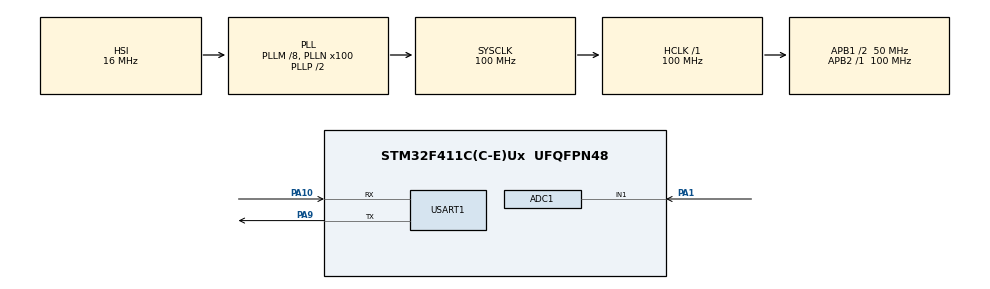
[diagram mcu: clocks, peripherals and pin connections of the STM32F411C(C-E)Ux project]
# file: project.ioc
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ADC1.Channel-0\#ChannelRegularConversion=ADC_CHANNEL_1
ADC1.ContinuousConvMode=ENABLE
ADC1.NbrOfConversionFlag=1
ADC1.Rank-0\#ChannelRegularConversion=1
ADC1.SamplingTime-0\#ChannelRegularConversion=ADC_SAMPLETIME_3CYCLES
ADC1.master=1
Dma.ADC1.0.Direction=DMA_PERIPH_TO_MEMORY
Dma.ADC1.0.FIFOMode=DMA_FIFOMODE_DISABLE
Dma.ADC1.0.Instance=DMA2_Stream0
Dma.ADC1.0.MemDataAlignment=DMA_MDATAALIGN_HALFWORD
Dma.ADC1.0.MemInc=DMA_MINC_ENABLE
Dma.ADC1.0.Mode=DMA_CIRCULAR
Dma.ADC1.0.PeriphDataAlignment=DMA_PDATAALIGN_HALFWORD
Dma.ADC1.0.PeriphInc=DMA_PINC_DISABLE
Dma.ADC1.0.Priority=DMA_PRIORITY_LOW
Dma.Request0=ADC1
FREERTOS.Tasks01=defaultTask,24,128,StartDefaultTask,Default,NULL,Dynamic,NULL,NULL
Mcu.Family=STM32F4
Mcu.Name=STM32F411C(C-E)Ux
Mcu.Package=UFQFPN48
NVIC.ADC_IRQn=true\:5\:0\:false\:false\:true\:true\:true\:true\:true
NVIC.DMA2_Stream0_IRQn=true\:5\:0\:false\:false\:true\:true\:false\:true\:true
NVIC.PriorityGroup=NVIC_PRIORITYGROUP_4
NVIC.TIM1_UP_TIM10_IRQn=true\:15\:0\:false\:false\:true\:false\:false\:true\:true
NVIC.TimeBase=TIM1_UP_TIM10_IRQn
NVIC.TimeBaseIP=TIM1
PA1.Signal=ADCx_IN1
PA10.Mode=Asynchronous
PA10.Signal=USART1_RX
PA13.Mode=Serial_Wire
PA13.Signal=SYS_JTMS-SWDIO
PA14.Mode=Serial_Wire
PA14.Signal=SYS_JTCK-SWCLK
PA9.Mode=Asynchronous
PA9.Signal=USART1_TX
ProjectManager.HeapSize=0x200
ProjectManager.StackSize=0x400
ProjectManager.TargetToolchain=MDK-ARM V5.32
RCC.48MHZClocksFreq_Value=50000000
RCC.AHBFreq_Value=100000000
RCC.APB1CLKDivider=RCC_HCLK_DIV2
RCC.APB1Freq_Value=50000000
RCC.APB1TimFreq_Value=100000000
RCC.APB2Freq_Value=100000000
RCC.APB2TimFreq_Value=100000000
RCC.CortexFreq_Value=100000000
RCC.HCLKFreq_Value=100000000
RCC.HSE_VALUE=25000000
RCC.HSI_VALUE=16000000
RCC.LSE_VALUE=32768
RCC.PLLM=8
RCC.PLLN=100
RCC.SYSCLKFreq_VALUE=100000000
RCC.SYSCLKSource=RCC_SYSCLKSOURCE_PLLCLK
RCC.VCOOutputFreq_Value=200000000
SH.ADCx_IN1.0=ADC1_IN1,IN1
USART1.VirtualMode=VM_ASYNC
VP_FREERTOS_VS_CMSIS_V2.Mode=CMSIS_V2
VP_SYS_VS_tim1.Mode=TIM1
board=custom

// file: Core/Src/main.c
/* USER CODE BEGIN Header */
/**
  ******************************************************************************
  * @file           : main.c
  * @brief          : Main program body
  ******************************************************************************
  * @attention
  *
  * Copyright (c) 2025 STMicroelectronics.
  * All rights reserved.
  *
  * This software is licensed under terms that can be found in the LICENSE file
  * in the root directory of this software component.
  * If no LICENSE file comes with this software, it is provided AS-IS.
  *
  ******************************************************************************
  */
/* USER CODE END Header */
#include "main.h"
#include "cmsis_os.h"

/* USER CODE BEGIN Includes */
#include "stdio.h"
#include "stdlib.h"
#include "elog.h"
/* USER CODE END Includes */

ADC_HandleTypeDef hadc1;
DMA_HandleTypeDef hdma_adc1;

UART_HandleTypeDef huart1;

/* Definitions for defaultTask */
osThreadId_t defaultTaskHandle;
const osThreadAttr_t defaultTask_attributes = {
  .name = "defaultTask",
  .stack_size = 128 * 4,
  .priority = (osPriority_t) osPriorityNormal,
};
/* USER CODE BEGIN PV */
uint32_t *buffer;
uint32_t *buffer1;
uint32_t *buffer2;
extern uint16_t ADC_VAL;
/* USER CODE END PV */

void SystemClock_Config(void);
static void MX_GPIO_Init(void);
static void MX_DMA_Init(void);
static void MX_ADC1_Init(void);
static void MX_USART1_UART_Init(void);
void StartDefaultTask(void *argument);

/* USER CODE BEGIN PFP */
void MX_FREERTOS_Init(void);
/* USER CODE END PFP */

/* USER CODE BEGIN 0 */
int fputc(int ch, FILE *f)
{
    HAL_UART_Transmit(&huart1, (uint8_t *)&ch, 1, 0xFFFF);

    return ch;
}

void app_elog_init(void){
	elog_init();

//    elog_set_text_color_enabled(true);

//    elog_set_fmt(ELOG_LVL_ASSERT,ELOG_FMT_ALL);

	elog_set_fmt(ELOG_LVL_ASSERT,ELOG_FMT_TIME | ELOG_FMT_LVL | ELOG_FMT_TAG | ELOG_FMT_DIR | ELOG_FMT_LINE | ELOG_FMT_FUNC);
	elog_set_fmt(ELOG_LVL_DEBUG,ELOG_FMT_TIME | ELOG_FMT_LVL | ELOG_FMT_TAG | ELOG_FMT_DIR | ELOG_FMT_LINE | ELOG_FMT_FUNC);
	elog_set_fmt(ELOG_LVL_ERROR,ELOG_FMT_TIME | ELOG_FMT_LVL | ELOG_FMT_TAG | ELOG_FMT_DIR | ELOG_FMT_LINE | ELOG_FMT_FUNC);
	elog_set_fmt(ELOG_LVL_INFO,ELOG_FMT_TIME | ELOG_FMT_LVL | ELOG_FMT_TAG | ELOG_FMT_DIR | ELOG_FMT_LINE | ELOG_FMT_FUNC);
	elog_set_fmt(ELOG_LVL_WARN,ELOG_FMT_TIME | ELOG_FMT_LVL | ELOG_FMT_TAG | ELOG_FMT_DIR | ELOG_FMT_LINE | ELOG_FMT_FUNC);

	elog_start();
}
/* USER CODE END 0 */

int main(void)
{

  /* USER CODE BEGIN 1 */
    buffer1= (uint32_t*)malloc(sizeof(uint32_t)*1);
    buffer2= (uint32_t*)malloc(sizeof(uint32_t)*1);
  /* USER CODE END 1 */

  /* MCU Configuration--------------------------------------------------------*/

  /* Reset of all peripherals, Initializes the Flash interface and the Systick. */
  HAL_Init();

  /* Configure the system clock */
  SystemClock_Config();

  /* Initialize all configured peripherals */
  MX_GPIO_Init();
  MX_DMA_Init();
  MX_ADC1_Init();
  MX_USART1_UART_Init();
  /* USER CODE BEGIN 2 */
    app_elog_init();
    elog_a(TAG,"hello");
    buffer = buffer1;
    HAL_ADC_Start_DMA(&hadc1, (uint32_t *)buffer, 1);
//    HAL_ADC_Start_IT(&hadc1);
  /* USER CODE END 2 */

  /* Init scheduler */
  osKernelInitialize();

  /* USER CODE BEGIN RTOS_MUTEX */
    MX_FREERTOS_Init();
  /* USER CODE END RTOS_MUTEX */

  /* Create the thread(s) */
  /* creation of defaultTask */
  defaultTaskHandle = osThreadNew(StartDefaultTask, NULL, &defaultTask_attributes);

  /* Start scheduler */
  osKernelStart();

  /* We should never get here as control is now taken by the scheduler */

  /* Infinite loop */
  while (1)
  {

  }
}

void SystemClock_Config(void)
{
  RCC_OscInitTypeDef RCC_OscInitStruct = {0};
  RCC_ClkInitTypeDef RCC_ClkInitStruct = {0};

  /** Configure the main internal regulator output voltage
  */
  __HAL_RCC_PWR_CLK_ENABLE();
  __HAL_PWR_VOLTAGESCALING_CONFIG(PWR_REGULATOR_VOLTAGE_SCALE1);

  /** Initializes the RCC Oscillators according to the specified parameters
  * in the RCC_OscInitTypeDef structure.
  */
  RCC_OscInitStruct.OscillatorType = RCC_OSCILLATORTYPE_HSI;
  RCC_OscInitStruct.HSIState = RCC_HSI_ON;
  RCC_OscInitStruct.HSICalibrationValue = RCC_HSICALIBRATION_DEFAULT;
  RCC_OscInitStruct.PLL.PLLState = RCC_PLL_ON;
  RCC_OscInitStruct.PLL.PLLSource = RCC_PLLSOURCE_HSI;
  RCC_OscInitStruct.PLL.PLLM = 8;
  RCC_OscInitStruct.PLL.PLLN = 100;
  RCC_OscInitStruct.PLL.PLLP = RCC_PLLP_DIV2;
  RCC_OscInitStruct.PLL.PLLQ = 4;
  if (HAL_RCC_OscConfig(&RCC_OscInitStruct) != HAL_OK)
  {
    Error_Handler();
  }

  /** Initializes the CPU, AHB and APB buses clocks
  */
  RCC_ClkInitStruct.ClockType = RCC_CLOCKTYPE_HCLK|RCC_CLOCKTYPE_SYSCLK
                              |RCC_CLOCKTYPE_PCLK1|RCC_CLOCKTYPE_PCLK2;
  RCC_ClkInitStruct.SYSCLKSource = RCC_SYSCLKSOURCE_PLLCLK;
  RCC_ClkInitStruct.AHBCLKDivider = RCC_SYSCLK_DIV1;
  RCC_ClkInitStruct.APB1CLKDivider = RCC_HCLK_DIV2;
  RCC_ClkInitStruct.APB2CLKDivider = RCC_HCLK_DIV1;

  if (HAL_RCC_ClockConfig(&RCC_ClkInitStruct, FLASH_LATENCY_3) != HAL_OK)
  {
    Error_Handler();
  }
}

static void MX_ADC1_Init(void)
{

  ADC_ChannelConfTypeDef sConfig = {0};

  /** Configure the global features of the ADC (Clock, Resolution, Data Alignment and number of conversion)
  */
  hadc1.Instance = ADC1;
  hadc1.Init.ClockPrescaler = ADC_CLOCK_SYNC_PCLK_DIV4;
  hadc1.Init.Resolution = ADC_RESOLUTION_12B;
  hadc1.Init.ScanConvMode = DISABLE;
  hadc1.Init.ContinuousConvMode = ENABLE;
  hadc1.Init.DiscontinuousConvMode = DISABLE;
  hadc1.Init.ExternalTrigConvEdge = ADC_EXTERNALTRIGCONVEDGE_NONE;
  hadc1.Init.ExternalTrigConv = ADC_SOFTWARE_START;
  hadc1.Init.DataAlign = ADC_DATAALIGN_RIGHT;
  hadc1.Init.NbrOfConversion = 1;
  hadc1.Init.DMAContinuousRequests = DISABLE;
  hadc1.Init.EOCSelection = ADC_EOC_SINGLE_CONV;
  if (HAL_ADC_Init(&hadc1) != HAL_OK)
  {
    Error_Handler();
  }

  /** Configure for the selected ADC regular channel its corresponding rank in the sequencer and its sample time.
  */
  sConfig.Channel = ADC_CHANNEL_1;
  sConfig.Rank = 1;
  sConfig.SamplingTime = ADC_SAMPLETIME_3CYCLES;
  if (HAL_ADC_ConfigChannel(&hadc1, &sConfig) != HAL_OK)
  {
    Error_Handler();
  }

}

static void MX_USART1_UART_Init(void)
{

  huart1.Instance = USART1;
  huart1.Init.BaudRate = 115200;
  huart1.Init.WordLength = UART_WORDLENGTH_8B;
  huart1.Init.StopBits = UART_STOPBITS_1;
  huart1.Init.Parity = UART_PARITY_NONE;
  huart1.Init.Mode = UART_MODE_TX_RX;
  huart1.Init.HwFlowCtl = UART_HWCONTROL_NONE;
  huart1.Init.OverSampling = UART_OVERSAMPLING_16;
  if (HAL_UART_Init(&huart1) != HAL_OK)
  {
    Error_Handler();
  }

}

static void MX_DMA_Init(void)
{

  /* DMA controller clock enable */
  __HAL_RCC_DMA2_CLK_ENABLE();

  /* DMA interrupt init */
  /* DMA2_Stream0_IRQn interrupt configuration */
  HAL_NVIC_SetPriority(DMA2_Stream0_IRQn, 5, 0);
  HAL_NVIC_EnableIRQ(DMA2_Stream0_IRQn);

}

static void MX_GPIO_Init(void)
{

  /* GPIO Ports Clock Enable */
  __HAL_RCC_GPIOA_CLK_ENABLE();

}

void StartDefaultTask(void *argument)
{
  /* USER CODE BEGIN 5 */
  /* Infinite loop */
  for(;;)
  {
    HAL_ADC_Start_DMA(&hadc1, (uint32_t *)buffer1, 1);
    osDelay(1);
  }
  /* USER CODE END 5 */
}

void HAL_TIM_PeriodElapsedCallback(TIM_HandleTypeDef *htim)
{
  if (htim->Instance == TIM1)
  {
    HAL_IncTick();
  }
}

void Error_Handler(void)
{
  __disable_irq();
  while (1)
  {
  }
}

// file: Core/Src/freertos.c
/* USER CODE BEGIN Header */
/**
  ******************************************************************************
  * File Name          : freertos.c
  * Description        : Code for freertos applications
  ******************************************************************************
  * @attention
  *
  * Copyright (c) 2025 STMicroelectronics.
  * All rights reserved.
  *
  * This software is licensed under terms that can be found in the LICENSE file
  * in the root directory of this software component.
  * If no LICENSE file comes with this software, it is provided AS-IS.
  *
  ******************************************************************************
  */
/* USER CODE END Header */

#include "FreeRTOS.h"
#include "task.h"
#include "main.h"

/* USER CODE BEGIN Includes */
#include "cmsis_os.h"
#include "elog.h"
/* USER CODE END Includes */

/* USER CODE BEGIN Variables */
osThreadId_t Task_ShowHandle, Task_AHandle, Task_BHandle;
const osThreadAttr_t Task_Show_attributes = {
    .name = "Task_Show",
    .priority = (osPriority_t)osPriorityNormal,
    .stack_size = 256 * 4
};

const osThreadAttr_t Task_A_attributes = {
    .name = "Task_A",
    .priority = (osPriority_t)osPriorityNormal,
    .stack_size = 256 * 4
};

const osThreadAttr_t Task_B_attributes = {
    .name = "Task_B",
    .priority = (osPriority_t)osPriorityNormal,
    .stack_size = 256 * 4
};

uint8_t cnt = 0;
uint32_t ADCtemp;
//uint32_t ulConversionResult;
extern uint32_t *buffer;
extern uint32_t *buffer1;
extern uint32_t *buffer2;
/* USER CODE END Variables */

/* USER CODE BEGIN FunctionPrototypes */
void AppTask_Show(void *argument);
void AppTask_A(void *argument);
void AppTask_B(void *argument);
void MX_FREERTOS_Init(void);

void MX_FREERTOS_Init(void)
{
//    Task_ShowHandle = osThreadNew(AppTask_Show, NULL, &Task_Show_attributes);
    Task_AHandle = osThreadNew(AppTask_A, NULL, &Task_A_attributes);
    Task_BHandle = osThreadNew(AppTask_B, NULL, &Task_B_attributes);
}
/* USER CODE END FunctionPrototypes */

/* USER CODE BEGIN Application */
void AppTask_Show(void *argument)
{
    uint32_t notifyValue = 0;

    for(;;)
    {
        uint32_t ulBitsToClearOnEntry = 0x00;
        uint32_t ulBitsToClearOnExit = 0xFFFFFFFF;
        BaseType_t result = xTaskNotifyWait(ulBitsToClearOnEntry, ulBitsToClearOnExit,
                                            &notifyValue, portMAX_DELAY);

        if(result == pdTRUE)
        {
            uint32_t tmpValue = notifyValue;
            uint32_t Volt = 3300 * tmpValue;
            Volt = Volt >> 12;
        }
    }
}

void AppTask_A(void *argument)
{
    uint32_t notifyValue = 0;

    for(;;)
    {
        uint32_t ulBitsToClearOnEntry = 0x00;
        uint32_t ulBitsToClearOnExit = 0xFFFFFFFF;
        BaseType_t result = xTaskNotifyWait(ulBitsToClearOnEntry,
                                            ulBitsToClearOnExit,
                                            &notifyValue,
                                            portMAX_DELAY);

        if(result == pdTRUE)
        {
            ADCtemp = notifyValue;
            // change buffer to buffer2
            if(++cnt%2 == 0)
            {
                buffer = buffer2;
                elog_a(TAG,"buffer = buffer2");
            }
            else
            {
                buffer = buffer1;
                elog_a(TAG,"buffer = buffer1");
            }

            xTaskNotify(Task_BHandle,
                        notifyValue,
                        eSetValueWithOverwrite);
        }
    }
}

void AppTask_B(void *argument)
{
    uint32_t notifyValue = 0;

    for(;;)
    {
        uint32_t ulBitsToClearOnEntry = 0x00;
        uint32_t ulBitsToClearOnExit = 0xFFFFFFFF;
        BaseType_t result = xTaskNotifyWait(ulBitsToClearOnEntry,
                                            ulBitsToClearOnExit,
                                            &notifyValue,
                                            portMAX_DELAY);

        if(result == pdTRUE)
        {
            uint32_t Volt;
            ADCtemp = notifyValue;
            Volt = 3300*notifyValue;
            ADCtemp = Volt;
            Volt = Volt>>12;
            ADCtemp = Volt;
            elog_a(TAG,"Volt = %d", Volt);
        }
    }
}

void HAL_ADC_ConvCpltCallback(ADC_HandleTypeDef *hadc)
{
    uint32_t ulConversionResult;

    if(hadc->Instance != ADC1)
        return;

    ulConversionResult = HAL_ADC_GetValue(hadc);

    if(Task_AHandle != NULL)
    {
        BaseType_t taskWoken = pdFALSE;
        xTaskNotifyFromISR(Task_AHandle,
                            ulConversionResult,
                            eSetValueWithOverwrite,
                            &taskWoken);
        portYIELD_FROM_ISR(taskWoken);
    }
}
/* USER CODE END Application */
